# f280015x_lcm_regs register map
Vendor: Texas Instruments
Peripheral module from a debugger description file (folder C2000).
Address unit: 16 bits
Registers are 32-bit, read-write, no defined reset value unless marked. A register's access mark holds for its fields unless they carry their own. Offsets are as the file gives them; lines under a group give offsets from that group; [hi:lo] are bit positions; {n}, {i} and the like mark numbered series; 'fields as' and 'values as' point back to an identical list; <NAME> marks a mode.

## LCM_REGS — LCM Registers
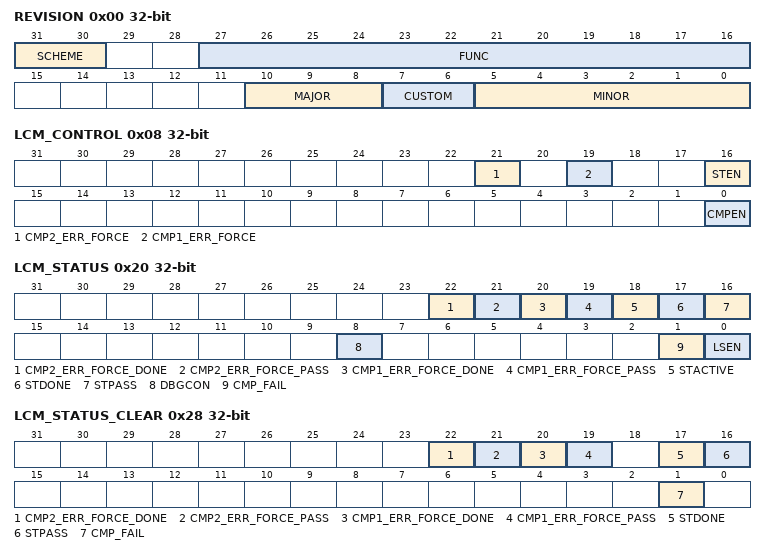
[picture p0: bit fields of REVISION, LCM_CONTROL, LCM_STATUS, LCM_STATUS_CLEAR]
0x00 REVISION ro — IP Revision tie-off value
  [31:30] SCHEME — Defines Scheme for Module
  [27:16] FUNC — Functional Release Number
  [10:8] MAJOR — Major Revision Number
  [7:6] CUSTOM — Custom Module Number
  [5:0] MINOR — Minor Revision Number
0x08 LCM_CONTROL — LCM Control configuration
  [21] CMP2_ERR_FORCE — Force error on comparator-2 lockstep compare error output
  [19] CMP1_ERR_FORCE — Force error on comparator-1 lockstep compare error output
  [16] STEN — Self-test enable
  [0] CMPEN — Enable/disable configuration for lockstep compare.
0x20 LCM_STATUS ro
  [22] CMP2_ERR_FORCE_DONE — completion status of comparator2 func error forcing
  [21] CMP2_ERR_FORCE_PASS — fail status of comparator2 func error forcing
  [20] CMP1_ERR_FORCE_DONE — completion status of comparator1 func error forcing
  [19] CMP1_ERR_FORCE_PASS — fail status of comparator1 func error forcing
  [18] STACTIVE — self-test active status indication
  [17] STDONE — self-test completion status
  [16] STPASS — self-test pass/fail status
  [8] DBGCON — debugger connected status information
  [1] CMP_FAIL — Pass/fail status of lockstep compare
  [0] LSEN — Lockstep configuration status
0x28 LCM_STATUS_CLEAR access per field
  [22] CMP2_ERR_FORCE_DONE rw — clear cmp2_func_error_force_done_status
  [21] CMP2_ERR_FORCE_PASS rw — clear cmp2_func_error_force_fail_status
  [20] CMP1_ERR_FORCE_DONE rw — clear cmp1_func_error_force_done_status
  [19] CMP1_ERR_FORCE_PASS rw — clear cmp1_func_error_force_fail_status
  [17] STDONE rw — clear Self-test_done_status
  [16] STPASS rw — clear Self-test_fail_status
  [1] CMP_FAIL rw — Clear lockstep compare fail status
0x68 PARITY_TEST — Enabling the parity test feature
  [3:0] TESTEN — Parity test enable configuration
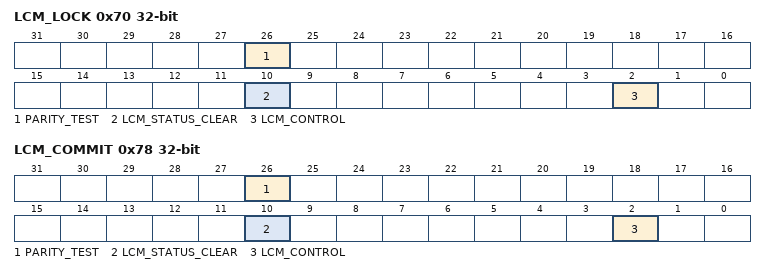
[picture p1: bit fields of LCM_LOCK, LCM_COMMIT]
0x70 LCM_LOCK — LCM lock configuration
  [26] PARITY_TEST — Register lock configuration
  [10] LCM_STATUS_CLEAR — Register lock configuration
  [2] LCM_CONTROL — Register lock configuration
0x78 LCM_COMMIT — LCM commit configuration
  [26] PARITY_TEST — Register commit configuration
  [10] LCM_STATUS_CLEAR — Register commit configuration
  [2] LCM_CONTROL — Register commit configuration
